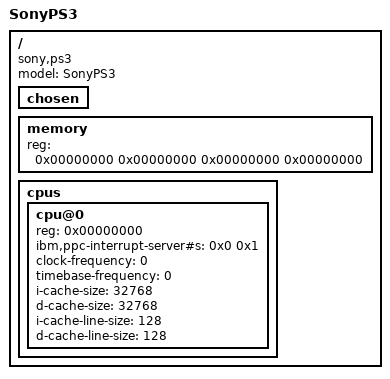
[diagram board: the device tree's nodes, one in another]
/dts-v1/;
/ {
	model = "SonyPS3";
	compatible = "sony,ps3";
	#size-cells = <2>;
	#address-cells = <2>;
	chosen {
	};
	memory {
		device_type = "memory";
		reg = <0x00000000 0x00000000 0x00000000 0x00000000>;
	};
	cpus {
		#size-cells = <0>;
		#address-cells = <1>;
		cpu@0 {
			device_type = "cpu";
			reg = <0x00000000>;
			ibm,ppc-interrupt-server#s = <0x0 0x1>;
			clock-frequency = <0>;
			timebase-frequency = <0>;
			i-cache-size = <32768>;
			d-cache-size = <32768>;
			i-cache-line-size = <128>;
			d-cache-line-size = <128>;
		};
	};
};
